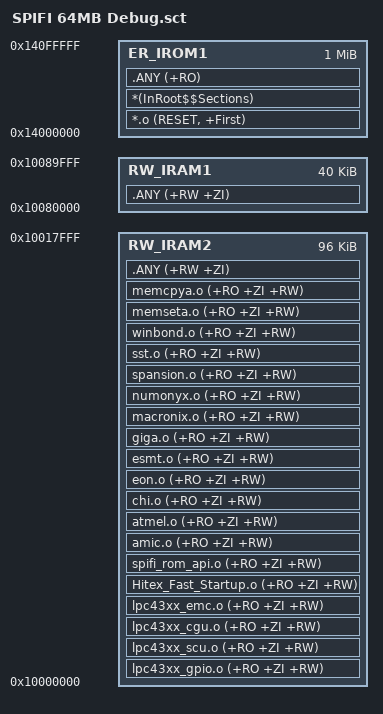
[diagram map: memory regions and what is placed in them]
; *************************************************************
; *** Scatter-Loading Description File generated by uVision ***
; *************************************************************

LR_IROM1 0x14000000 0x00100000  {    ; load region size_region
  ER_IROM1 0x14000000 0x00100000  {  ; load address = execution address
   *.o (RESET, +First)
   *(InRoot$$Sections)
   .ANY (+RO)
  }
  RW_IRAM1 0x10080000 0x0000A000  {  ; RW data
   .ANY (+RW +ZI)
  }
  RW_IRAM2 0x10000000 0x00018000  {
    lpc43xx_gpio.o (+RO +ZI +RW)
    lpc43xx_scu.o (+RO +ZI +RW)
    lpc43xx_cgu.o (+RO +ZI +RW)
    lpc43xx_emc.o (+RO +ZI +RW)
    Hitex_Fast_Startup.o (+RO +ZI +RW)
    spifi_rom_api.o (+RO +ZI +RW)
	amic.o (+RO +ZI +RW)
	atmel.o (+RO +ZI +RW)
	chi.o (+RO +ZI +RW)
	eon.o (+RO +ZI +RW)
	esmt.o (+RO +ZI +RW)
	giga.o (+RO +ZI +RW)
	macronix.o (+RO +ZI +RW)
	numonyx.o (+RO +ZI +RW)
	spansion.o (+RO +ZI +RW)
	sst.o (+RO +ZI +RW)
	winbond.o (+RO +ZI +RW)
	memseta.o (+RO +ZI +RW)
	memcpya.o (+RO +ZI +RW)
   .ANY (+RW +ZI)
  }
}

